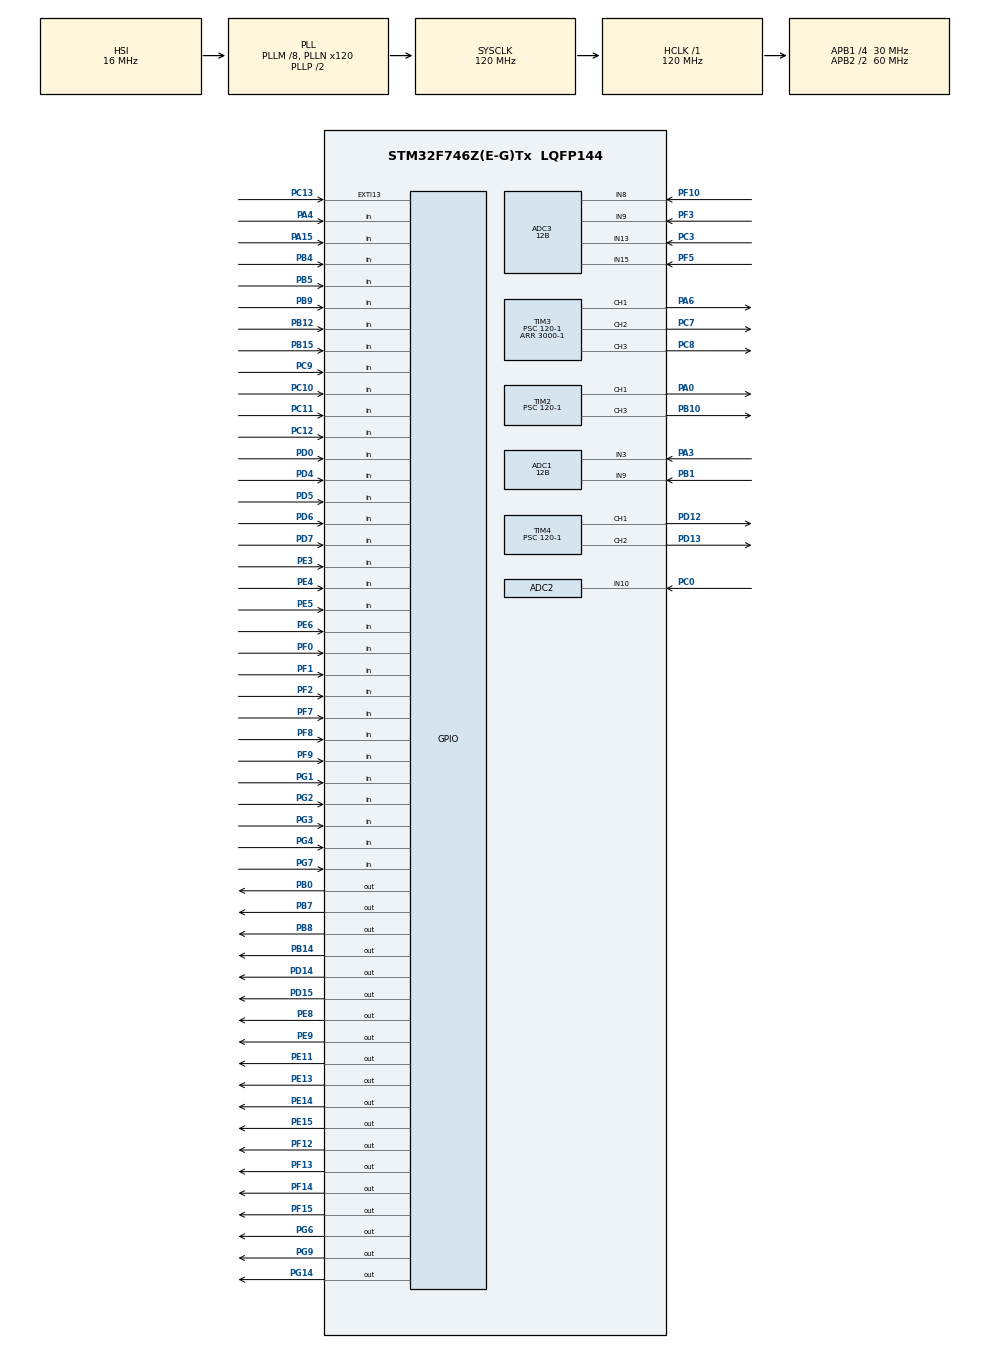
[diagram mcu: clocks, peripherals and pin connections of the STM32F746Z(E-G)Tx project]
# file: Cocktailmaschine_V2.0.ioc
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ADC1.Channel-10\#ChannelRegularConversion=ADC_CHANNEL_TEMPSENSOR
ADC1.Channel-5\#ChannelRegularConversion=ADC_CHANNEL_3
ADC1.Channel-6\#ChannelRegularConversion=ADC_CHANNEL_9
ADC1.ClockPrescaler=ADC_CLOCK_SYNC_PCLK_DIV4
ADC1.ContinuousConvMode=ENABLE
ADC1.DMAContinuousRequests=ENABLE
ADC1.DataAlign=ADC_DATAALIGN_RIGHT
ADC1.DiscontinuousConvMode=DISABLE
ADC1.EOCSelection=ADC_EOC_SINGLE_CONV
ADC1.EnableAnalogWatchDog=false
ADC1.ExternalTrigConv=ADC_SOFTWARE_START
ADC1.ExternalTrigConvEdge=ADC_EXTERNALTRIGCONVEDGE_NONE
ADC1.InjNumberOfConversion=0
ADC1.NbrOfConversion=3
ADC1.NbrOfConversionFlag=1
ADC1.Rank-10\#ChannelRegularConversion=3
ADC1.Rank-5\#ChannelRegularConversion=1
ADC1.Rank-6\#ChannelRegularConversion=2
ADC1.Resolution=ADC_RESOLUTION_12B
ADC1.SamplingTime-10\#ChannelRegularConversion=ADC_SAMPLETIME_28CYCLES
ADC1.SamplingTime-5\#ChannelRegularConversion=ADC_SAMPLETIME_28CYCLES
ADC1.SamplingTime-6\#ChannelRegularConversion=ADC_SAMPLETIME_28CYCLES
ADC1.ScanConvMode=ENABLE
ADC1.master=1
ADC2.Channel-0\#ChannelRegularConversion=ADC_CHANNEL_10
ADC2.ClockPrescaler=ADC_CLOCK_SYNC_PCLK_DIV4
ADC2.ContinuousConvMode=ENABLE
ADC2.DMAContinuousRequests=ENABLE
ADC2.DataAlign=ADC_DATAALIGN_RIGHT
ADC2.DiscontinuousConvMode=DISABLE
ADC2.EOCSelection=ADC_EOC_SINGLE_CONV
ADC2.EnableAnalogWatchDog=false
ADC2.ExternalTrigConv=ADC_SOFTWARE_START
ADC2.ExternalTrigConvEdge=ADC_EXTERNALTRIGCONVEDGE_NONE
ADC2.InjNumberOfConversion=0
ADC2.NbrOfConversion=1
ADC2.NbrOfConversionFlag=1
ADC2.Rank-0\#ChannelRegularConversion=1
ADC2.Resolution=ADC_RESOLUTION_12B
ADC2.SamplingTime-0\#ChannelRegularConversion=ADC_SAMPLETIME_28CYCLES
ADC2.ScanConvMode=ENABLE
ADC3.Channel-0\#ChannelRegularConversion=ADC_CHANNEL_8
ADC3.Channel-1\#ChannelRegularConversion=ADC_CHANNEL_9
ADC3.Channel-2\#ChannelRegularConversion=ADC_CHANNEL_13
ADC3.Channel-3\#ChannelRegularConversion=ADC_CHANNEL_15
ADC3.ClockPrescaler=ADC_CLOCK_SYNC_PCLK_DIV4
ADC3.ContinuousConvMode=ENABLE
ADC3.DMAContinuousRequests=ENABLE
ADC3.DataAlign=ADC_DATAALIGN_RIGHT
ADC3.DiscontinuousConvMode=DISABLE
ADC3.EOCSelection=ADC_EOC_SINGLE_CONV
ADC3.EnableAnalogWatchDog=false
ADC3.ExternalTrigConv=ADC_SOFTWARE_START
ADC3.ExternalTrigConvEdge=ADC_EXTERNALTRIGCONVEDGE_NONE
ADC3.InjNumberOfConversion=0
ADC3.NbrOfConversion=4
ADC3.NbrOfConversionFlag=1
ADC3.Rank-0\#ChannelRegularConversion=1
ADC3.Rank-1\#ChannelRegularConversion=2
ADC3.Rank-2\#ChannelRegularConversion=3
ADC3.Rank-3\#ChannelRegularConversion=4
ADC3.Resolution=ADC_RESOLUTION_12B
ADC3.SamplingTime-0\#ChannelRegularConversion=ADC_SAMPLETIME_28CYCLES
ADC3.SamplingTime-1\#ChannelRegularConversion=ADC_SAMPLETIME_28CYCLES
ADC3.SamplingTime-2\#ChannelRegularConversion=ADC_SAMPLETIME_28CYCLES
ADC3.SamplingTime-3\#ChannelRegularConversion=ADC_SAMPLETIME_28CYCLES
ADC3.ScanConvMode=ENABLE
Dma.ADC1.0.Direction=DMA_PERIPH_TO_MEMORY
Dma.ADC1.0.FIFOMode=DMA_FIFOMODE_DISABLE
Dma.ADC1.0.Instance=DMA2_Stream0
Dma.ADC1.0.MemDataAlignment=DMA_MDATAALIGN_WORD
Dma.ADC1.0.MemInc=DMA_MINC_ENABLE
Dma.ADC1.0.Mode=DMA_CIRCULAR
Dma.ADC1.0.PeriphDataAlignment=DMA_PDATAALIGN_WORD
Dma.ADC1.0.PeriphInc=DMA_PINC_DISABLE
Dma.ADC1.0.Priority=DMA_PRIORITY_LOW
Dma.ADC2.1.Direction=DMA_PERIPH_TO_MEMORY
Dma.ADC2.1.FIFOMode=DMA_FIFOMODE_DISABLE
Dma.ADC2.1.Instance=DMA2_Stream2
Dma.ADC2.1.MemDataAlignment=DMA_MDATAALIGN_WORD
Dma.ADC2.1.MemInc=DMA_MINC_ENABLE
Dma.ADC2.1.Mode=DMA_CIRCULAR
Dma.ADC2.1.PeriphDataAlignment=DMA_PDATAALIGN_WORD
Dma.ADC2.1.PeriphInc=DMA_PINC_DISABLE
Dma.ADC2.1.Priority=DMA_PRIORITY_LOW
Dma.ADC3.2.Direction=DMA_PERIPH_TO_MEMORY
Dma.ADC3.2.FIFOMode=DMA_FIFOMODE_DISABLE
Dma.ADC3.2.Instance=DMA2_Stream1
Dma.ADC3.2.MemDataAlignment=DMA_MDATAALIGN_WORD
Dma.ADC3.2.MemInc=DMA_MINC_ENABLE
Dma.ADC3.2.Mode=DMA_CIRCULAR
Dma.ADC3.2.PeriphDataAlignment=DMA_PDATAALIGN_WORD
Dma.ADC3.2.PeriphInc=DMA_PINC_DISABLE
Dma.ADC3.2.Priority=DMA_PRIORITY_LOW
Dma.Request0=ADC1
Dma.Request1=ADC2
Dma.Request2=ADC3
FREERTOS.INCLUDE_vTaskDelayUntil=1
FREERTOS.MEMORY_ALLOCATION=0
FREERTOS.Tasks01=mainCycle,0,256,mainCycleStart,Default,NULL,Dynamic,NULL,NULL;commTask,-1,128,initCommTask,Default,NULL,Dynamic,NULL,NULL
FREERTOS.Timers01=Timer_TestEnv,TestEnvCallback,osTimerPeriodic,Default,NULL,Dynamic,NULL
FREERTOS.configTOTAL_HEAP_SIZE=15000
FREERTOS.configUSE_COUNTING_SEMAPHORES=1
FREERTOS.configUSE_TIMERS=1
Mcu.Family=STM32F7
Mcu.Name=STM32F746Z(E-G)Tx
Mcu.Package=LQFP144
NVIC.DMA2_Stream0_IRQn=true\:5\:0\:false\:false\:true\:true
NVIC.DMA2_Stream1_IRQn=true\:5\:0\:false\:false\:true\:true
NVIC.DMA2_Stream2_IRQn=true\:5\:0\:false\:false\:true\:true
NVIC.PriorityGroup=NVIC_PRIORITYGROUP_4
NVIC.TIM1_UP_TIM10_IRQn=true\:0\:0\:false\:false\:true\:false
NVIC.TimeBase=TIM1_UP_TIM10_IRQn
NVIC.TimeBaseIP=TIM1
PA0/WKUP.Signal=S_TIM2_CH1_ETR
PA1.GPIO_Mode=GPIO_MODE_AF_PP
PA1.GPIO_PuPd=GPIO_NOPULL
PA1.GPIO_Speed=GPIO_SPEED_FREQ_VERY_HIGH
PA1.Signal=ETH_REF_CLK
PA10.GPIO_Mode=GPIO_MODE_AF_PP
PA10.GPIO_PuPd=GPIO_NOPULL
PA10.GPIO_Speed=GPIO_SPEED_FREQ_VERY_HIGH
PA10.Signal=USB_OTG_FS_ID
PA11.GPIO_Mode=GPIO_MODE_AF_PP
PA11.GPIO_PuPd=GPIO_NOPULL
PA11.GPIO_Speed=GPIO_SPEED_FREQ_VERY_HIGH
PA11.Signal=USB_OTG_FS_DM
PA12.GPIO_Mode=GPIO_MODE_AF_PP
PA12.GPIO_PuPd=GPIO_NOPULL
PA12.GPIO_Speed=GPIO_SPEED_FREQ_VERY_HIGH
PA12.Signal=USB_OTG_FS_DP
PA13.Signal=SYS_JTMS-SWDIO
PA14.Signal=SYS_JTCK-SWCLK
PA15.Signal=GPIO_Input
PA2.GPIO_Mode=GPIO_MODE_AF_PP
PA2.GPIO_PuPd=GPIO_NOPULL
PA2.GPIO_Speed=GPIO_SPEED_FREQ_VERY_HIGH
PA2.Signal=ETH_MDIO
PA3.Signal=SharedAnalog_PA3
PA4.GPIO_PuPd=GPIO_PULLUP
PA4.Signal=GPIO_Input
PA6.Signal=S_TIM3_CH1
PA7.GPIO_Mode=GPIO_MODE_AF_PP
PA7.GPIO_PuPd=GPIO_NOPULL
PA7.GPIO_Speed=GPIO_SPEED_FREQ_VERY_HIGH
PA7.Signal=ETH_CRS_DV
PA8.GPIO_Mode=GPIO_MODE_AF_PP
PA8.GPIO_PuPd=GPIO_NOPULL
PA8.GPIO_Speed=GPIO_SPEED_FREQ_VERY_HIGH
PA8.Signal=USB_OTG_FS_SOF
PA9.GPIO_Mode=GPIO_MODE_INPUT
PA9.GPIO_PuPd=GPIO_NOPULL
PA9.Signal=USB_OTG_FS_VBUS
PB0.GPIO_ModeDefaultOutputPP=GPIO_MODE_OUTPUT_PP
PB0.GPIO_PuPd=GPIO_NOPULL
PB0.GPIO_Speed=GPIO_SPEED_FREQ_LOW
PB0.PinState=GPIO_PIN_RESET
PB0.Signal=GPIO_Output
PB1.Signal=SharedAnalog_PB1
PB10.Signal=S_TIM2_CH3
PB12.GPIO_PuPd=GPIO_PULLUP
PB12.Signal=GPIO_Input
PB13.GPIO_Mode=GPIO_MODE_AF_PP
PB13.GPIO_PuPd=GPIO_NOPULL
PB13.GPIO_Speed=GPIO_SPEED_FREQ_VERY_HIGH
PB13.Signal=ETH_TXD1
PB14.GPIO_ModeDefaultOutputPP=GPIO_MODE_OUTPUT_PP
PB14.GPIO_PuPd=GPIO_NOPULL
PB14.GPIO_Speed=GPIO_SPEED_FREQ_LOW
PB14.PinState=GPIO_PIN_RESET
PB14.Signal=GPIO_Output
PB15.Signal=GPIO_Input
PB3.Signal=SYS_JTDO-SWO
PB4.GPIO_PuPd=GPIO_PULLUP
PB4.Signal=GPIO_Input
PB5.GPIO_PuPd=GPIO_PULLUP
PB5.Signal=GPIO_Input
PB7.GPIO_ModeDefaultOutputPP=GPIO_MODE_OUTPUT_PP
PB7.GPIO_PuPd=GPIO_NOPULL
PB7.GPIO_Speed=GPIO_SPEED_FREQ_LOW
PB7.PinState=GPIO_PIN_RESET
PB7.Signal=GPIO_Output
PB8.Signal=GPIO_Output
PB9.Signal=GPIO_Input
PC0.Signal=SharedAnalog_PC0
PC1.GPIO_Mode=GPIO_MODE_AF_PP
PC1.GPIO_PuPd=GPIO_NOPULL
PC1.GPIO_Speed=GPIO_SPEED_FREQ_VERY_HIGH
PC1.Signal=ETH_MDC
PC10.GPIO_Mode=GPIO_MODE_INPUT
PC10.GPIO_PuPd=GPIO_PULLUP
PC10.Signal=GPIO_Input
PC11.GPIO_Mode=GPIO_MODE_INPUT
PC11.GPIO_PuPd=GPIO_PULLUP
PC11.Signal=GPIO_Input
PC12.GPIO_Mode=GPIO_MODE_INPUT
PC12.GPIO_PuPd=GPIO_PULLUP
PC12.Signal=GPIO_Input
PC13.GPIO_ModeDefaultEXTI=GPIO_MODE_IT_RISING
PC13.GPIO_PuPd=GPIO_NOPULL
PC13.Signal=GPXTI13
PC14/OSC32_IN.Signal=RCC_OSC32_IN
PC15/OSC32_OUT.Signal=RCC_OSC32_OUT
PC3.Signal=SharedAnalog_PC3
PC4.GPIO_Mode=GPIO_MODE_AF_PP
PC4.GPIO_PuPd=GPIO_NOPULL
PC4.GPIO_Speed=GPIO_SPEED_FREQ_VERY_HIGH
PC4.Signal=ETH_RXD0
PC5.GPIO_Mode=GPIO_MODE_AF_PP
PC5.GPIO_PuPd=GPIO_NOPULL
PC5.GPIO_Speed=GPIO_SPEED_FREQ_VERY_HIGH
PC5.Signal=ETH_RXD1
PC7.Signal=S_TIM3_CH2
PC8.Signal=S_TIM3_CH3
PC9.GPIO_Mode=GPIO_MODE_INPUT
PC9.GPIO_PuPd=GPIO_PULLUP
PC9.Signal=GPIO_Input
PD0.Signal=GPIO_Input
PD12.Signal=S_TIM4_CH1
PD13.Signal=S_TIM4_CH2
PD14.Signal=GPIO_Output
PD15.Signal=GPIO_Output
PD4.GPIO_Mode=GPIO_MODE_INPUT
PD4.GPIO_PuPd=GPIO_PULLUP
PD4.Signal=GPIO_Input
PD5.GPIO_Mode=GPIO_MODE_INPUT
PD5.GPIO_PuPd=GPIO_PULLUP
PD5.Signal=GPIO_Input
PD6.GPIO_Mode=GPIO_MODE_INPUT
PD6.GPIO_PuPd=GPIO_PULLUP
PD6.Signal=GPIO_Input
PD7.GPIO_Mode=GPIO_MODE_INPUT
PD7.GPIO_PuPd=GPIO_PULLUP
PD7.Signal=GPIO_Input
PD8.GPIO_Mode=GPIO_MODE_AF_PP
PD8.GPIO_PuPd=GPIO_NOPULL
PD8.GPIO_Speed=GPIO_SPEED_FREQ_VERY_HIGH
PD8.Signal=USART3_TX
PD9.GPIO_Mode=GPIO_MODE_AF_PP
PD9.GPIO_PuPd=GPIO_NOPULL
PD9.GPIO_Speed=GPIO_SPEED_FREQ_VERY_HIGH
PD9.Signal=USART3_RX
PE11.Signal=GPIO_Output
PE13.Signal=GPIO_Output
PE14.Signal=GPIO_Output
PE15.Signal=GPIO_Output
PE3.Signal=GPIO_Input
PE4.Signal=GPIO_Input
PE5.Signal=GPIO_Input
PE6.Signal=GPIO_Input
PE7.Signal=UART7_RX
PE8.Signal=GPIO_Output
PE9.Signal=GPIO_Output
PF0.Signal=GPIO_Input
PF1.Signal=GPIO_Input
PF10.Signal=SharedAnalog_PF10
PF12.Signal=GPIO_Output
PF13.Signal=GPIO_Output
PF14.Signal=GPIO_Output
PF15.Signal=GPIO_Output
PF2.Signal=GPIO_Input
PF3.Signal=SharedAnalog_PF3
PF5.Signal=SharedAnalog_PF5
PF7.GPIO_PuPd=GPIO_NOPULL
PF7.Signal=GPIO_Input
PF8.GPIO_PuPd=GPIO_NOPULL
PF8.Signal=GPIO_Input
PF9.Signal=GPIO_Input
PG1.GPIO_PuPd=GPIO_NOPULL
PG1.Signal=GPIO_Input
PG11.GPIO_Mode=GPIO_MODE_AF_PP
PG11.GPIO_PuPd=GPIO_NOPULL
PG11.GPIO_Speed=GPIO_SPEED_FREQ_VERY_HIGH
PG11.Signal=ETH_TX_EN
PG13.GPIO_Mode=GPIO_MODE_AF_PP
PG13.GPIO_PuPd=GPIO_NOPULL
PG13.GPIO_Speed=GPIO_SPEED_FREQ_VERY_HIGH
PG13.Signal=ETH_TXD0
PG14.Signal=GPIO_Output
PG2.GPIO_PuPd=GPIO_PULLUP
PG2.Signal=GPIO_Input
PG3.GPIO_PuPd=GPIO_PULLUP
PG3.Signal=GPIO_Input
PG4.GPIO_PuPd=GPIO_PULLUP
PG4.Signal=GPIO_Input
PG6.GPIO_ModeDefaultOutputPP=GPIO_MODE_OUTPUT_PP
PG6.GPIO_PuPd=GPIO_NOPULL
PG6.GPIO_Speed=GPIO_SPEED_FREQ_LOW
PG6.PinState=GPIO_PIN_RESET
PG6.Signal=GPIO_Output
PG7.GPIO_Mode=GPIO_MODE_INPUT
PG7.GPIO_PuPd=GPIO_NOPULL
PG7.Signal=GPIO_Input
PG9.Signal=GPIO_Output
PH0/OSC_IN.Signal=RCC_OSC_IN
PH1/OSC_OUT.Signal=RCC_OSC_OUT
ProjectManager.HeapSize=0x200
ProjectManager.StackSize=0x400
ProjectManager.TargetToolchain=TrueSTUDIO
RCC.48MHZClocksFreq_Value=24000000
RCC.AHBFreq_Value=120000000
RCC.APB1CLKDivider=RCC_HCLK_DIV4
RCC.APB1Freq_Value=30000000
RCC.APB1TimFreq_Value=60000000
RCC.APB2CLKDivider=RCC_HCLK_DIV2
RCC.APB2Freq_Value=60000000
RCC.APB2TimFreq_Value=120000000
RCC.CortexFreq_Value=120000000
RCC.HCLKFreq_Value=120000000
RCC.HSE_VALUE=8000000
RCC.HSI_VALUE=16000000
RCC.LSE_VALUE=32768
RCC.PLLM=8
RCC.PLLMUL=RCC_PLL_MUL9
RCC.PLLN=120
RCC.PLLQ=5
RCC.PRESCALERUSB=RCC_USBCLKSOURCE_PLL_DIV1_5
RCC.SYSCLKFreq_VALUE=120000000
RCC.SYSCLKSource=RCC_SYSCLKSOURCE_PLLCLK
RCC.SYSCLKSourceVirtual=RCC_SYSCLKSOURCE_PLLCLK
RCC.USBFreq_Value=48000000
RCC.VCOOutputFreq_Value=240000000
SH.S_TIM2_CH1_ETR.0=TIM2_CH1,PWM Generation1 CH1
SH.S_TIM2_CH3.0=TIM2_CH3,PWM Generation3 CH3
SH.S_TIM3_CH1.0=TIM3_CH1,PWM Generation1 CH1
SH.S_TIM3_CH2.0=TIM3_CH2,PWM Generation2 CH2
SH.S_TIM3_CH3.0=TIM3_CH3,PWM Generation3 CH3
SH.S_TIM4_CH1.0=TIM4_CH1,PWM Generation1 CH1
SH.S_TIM4_CH2.0=TIM4_CH2,PWM Generation2 CH2
SH.SharedAnalog_PA3.0=GPIO_Analog
SH.SharedAnalog_PA3.1=ADC1_IN3,IN3
SH.SharedAnalog_PB1.0=GPIO_Analog
SH.SharedAnalog_PB1.1=ADC1_IN9,IN9
SH.SharedAnalog_PC0.0=GPIO_Analog
SH.SharedAnalog_PC0.1=ADC2_IN10,IN10
SH.SharedAnalog_PC3.0=GPIO_Analog
SH.SharedAnalog_PC3.1=ADC3_IN13,IN13
SH.SharedAnalog_PF10.0=GPIO_Analog
SH.SharedAnalog_PF10.1=ADC3_IN8,IN8
SH.SharedAnalog_PF3.0=GPIO_Analog
SH.SharedAnalog_PF3.1=ADC3_IN9,IN9
SH.SharedAnalog_PF5.0=GPIO_Analog
SH.SharedAnalog_PF5.1=ADC3_IN15,IN15
TIM2.Channel-PWM\ Generation1\ CH1=TIM_CHANNEL_1
TIM2.Channel-PWM\ Generation3\ CH3=TIM_CHANNEL_3
TIM2.Period=3000-1
TIM2.Prescaler=120-1
TIM3.Channel-PWM\ Generation1\ CH1=TIM_CHANNEL_1
TIM3.Channel-PWM\ Generation2\ CH2=TIM_CHANNEL_2
TIM3.Channel-PWM\ Generation3\ CH3=TIM_CHANNEL_3
TIM3.Period=3000-1
TIM3.Prescaler=120-1
TIM4.Channel-PWM\ Generation1\ CH1=TIM_CHANNEL_1
TIM4.Channel-PWM\ Generation2\ CH2=TIM_CHANNEL_2
TIM4.Period=3000-1
TIM4.Prescaler=120-1
VP_ADC1_TempSens_Input.Mode=IN-TempSens
VP_FREERTOS_VS_ENABLE.Mode=Enabled
VP_SYS_VS_tim1.Mode=TIM1
board=NUCLEO-F746ZG

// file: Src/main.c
/**
  ******************************************************************************
  * File Name          : main.c
  * Description        : Main program body
  ******************************************************************************
  * This notice applies to any and all portions of this file
  * that are not between comment pairs USER CODE BEGIN and
  * USER CODE END. Other portions of this file, whether
  * inserted by the user or by software development tools
  * are owned by their respective copyright owners.
  *
  * Copyright (c) 2017 STMicroelectronics International N.V.
  * All rights reserved.
  *
  * Redistribution and use in source and binary forms, with or without
  * modification, are permitted, provided that the following conditions are met:
  *
  * 1. Redistribution of source code must retain the above copyright notice,
  *    this list of conditions and the following disclaimer.
  * 2. Redistributions in binary form must reproduce the above copyright notice,
  *    this list of conditions and the following disclaimer in the documentation
  *    and/or other materials provided with the distribution.
  * 3. Neither the name of STMicroelectronics nor the names of other
  *    contributors to this software may be used to endorse or promote products
  *    derived from this software without specific written permission.
  * 4. This software, including modifications and/or derivative works of this
  *    software, must execute solely and exclusively on microcontroller or
  *    microprocessor devices manufactured by or for STMicroelectronics.
  * 5. Redistribution and use of this software other than as permitted under
  *    this license is void and will automatically terminate your rights under
  *    this license.
  *
  * THIS SOFTWARE IS PROVIDED BY STMICROELECTRONICS AND CONTRIBUTORS "AS IS"
  * AND ANY EXPRESS, IMPLIED OR STATUTORY WARRANTIES, INCLUDING, BUT NOT
  * LIMITED TO, THE IMPLIED WARRANTIES OF MERCHANTABILITY, FITNESS FOR A
  * PARTICULAR PURPOSE AND NON-INFRINGEMENT OF THIRD PARTY INTELLECTUAL PROPERTY
  * RIGHTS ARE DISCLAIMED TO THE FULLEST EXTENT PERMITTED BY LAW. IN NO EVENT
  * SHALL STMICROELECTRONICS OR CONTRIBUTORS BE LIABLE FOR ANY DIRECT, INDIRECT,
  * INCIDENTAL, SPECIAL, EXEMPLARY, OR CONSEQUENTIAL DAMAGES (INCLUDING, BUT NOT
  * LIMITED TO, PROCUREMENT OF SUBSTITUTE GOODS OR SERVICES; LOSS OF USE, DATA,
  * OR PROFITS; OR BUSINESS INTERRUPTION) HOWEVER CAUSED AND ON ANY THEORY OF
  * LIABILITY, WHETHER IN CONTRACT, STRICT LIABILITY, OR TORT (INCLUDING
  * NEGLIGENCE OR OTHERWISE) ARISING IN ANY WAY OUT OF THE USE OF THIS SOFTWARE,
  * EVEN IF ADVISED OF THE POSSIBILITY OF SUCH DAMAGE.
  *
  ******************************************************************************
  */
#include "main.h"
#include "stm32f7xx_hal.h"
#include "cmsis_os.h"

/* USER CODE BEGIN Includes */
#include "Sensors.h"
#include "Evaluation.h"
#include "Module_5_Sensors.h"
#include "Module_common.h"
#include "Actuators.h"
#include "Communication.h"

#define DEBUG_ENABLED 1
#include "Debug.h"

#include "FreeRTOS.h"
#include "task.h"
#include "stm32f7xx_nucleo_144.h"

/* USER CODE END Includes */

ADC_HandleTypeDef hadc1;
ADC_HandleTypeDef hadc2;
ADC_HandleTypeDef hadc3;
DMA_HandleTypeDef hdma_adc1;
DMA_HandleTypeDef hdma_adc2;
DMA_HandleTypeDef hdma_adc3;

TIM_HandleTypeDef htim2;
TIM_HandleTypeDef htim3;
TIM_HandleTypeDef htim4;

osThreadId mainCycleHandle;
osThreadId commTaskHandle;
osTimerId Timer_TestEnvHandle;

/* USER CODE BEGIN PV */
/* Private variables ---------------------------------------------------------*/
InputValues_t Input_Storage;
OutputValues_t Output_Storage;
SystemState_t System_State;

osThreadId mainCycleHandle;

extern int virtual_testenv_timer_variable;

/* USER CODE END PV */

void SystemClock_Config(void);
static void MX_GPIO_Init(void);
static void MX_DMA_Init(void);
static void MX_ADC1_Init(void);
static void MX_ADC2_Init(void);
static void MX_ADC3_Init(void);
static void MX_TIM3_Init(void);
static void MX_TIM4_Init(void);
static void MX_TIM2_Init(void);
void mainCycleStart(void const * argument);
void initCommTask(void const * argument);
void TestEnvCallback(void const * argument);

void HAL_TIM_MspPostInit(TIM_HandleTypeDef *htim);

/* USER CODE BEGIN PFP */
/* Private function prototypes -----------------------------------------------*/

/* USER CODE END PFP */

int main(void)
{

  /* MCU Configuration----------------------------------------------------------*/

  /* Reset of all peripherals, Initializes the Flash interface and the Systick. */
  HAL_Init();

  /* Configure the system clock */
  SystemClock_Config();

  /* Initialize all configured peripherals */
  MX_GPIO_Init();
  MX_DMA_Init();
  MX_ADC1_Init();
  MX_ADC2_Init();
  MX_ADC3_Init();
  MX_TIM3_Init();
  MX_TIM4_Init();
  MX_TIM2_Init();

  /* USER CODE BEGIN 2 */
  if(HAL_ADC_Start(&hadc1) != HAL_OK)
  {
	  printf("ADC not ok! \r\n");
	  return 0;
  }
  if(HAL_ADC_Start_DMA(&hadc1, (uint32_t*)ADC1ConvertedValues,12)!= HAL_OK)
  {
	  printf("DMA not ok! \r\n");
	  return 0;
  }
  if(HAL_ADC_Start(&hadc2) != HAL_OK)
  {
	  printf("ADC not ok! \r\n");
	  return 0;
  }
  if(HAL_ADC_Start_DMA(&hadc2, (uint32_t*)ADC2ConvertedValues,1)!= HAL_OK)
  {
	  printf("DMA not ok! \r\n");
	  return 0;
  }
  if(HAL_ADC_Start(&hadc3) != HAL_OK)
  {
	  printf("ADC not ok! \r\n");
	  return 0;
  }
  if(HAL_ADC_Start_DMA(&hadc3, (uint32_t*)ADC3ConvertedValues,4)!= HAL_OK)
  {
	  printf("DMA not ok! \r\n");
	  return 0;
  }

  /*FreeRTOS_IPInit( ucIPAddress,
                   ucNetMask,
                   ucGatewayAddress,
                   ucDNSServerAddress,
                   ucMACAddress );*/
  /* USER CODE END 2 */

  /* Create the timer(s) */
  /* definition and creation of Timer_TestEnv */
  osTimerDef(Timer_TestEnv, TestEnvCallback);
  Timer_TestEnvHandle = osTimerCreate(osTimer(Timer_TestEnv), osTimerPeriodic, NULL);

  /* Create the thread(s) */
  /* definition and creation of mainCycle */
  osThreadDef(mainCycle, mainCycleStart, osPriorityNormal, 0, 256);
  mainCycleHandle = osThreadCreate(osThread(mainCycle), NULL);

  /* definition and creation of commTask */
  osThreadDef(commTask, initCommTask, osPriorityBelowNormal, 0, 128);
  commTaskHandle = osThreadCreate(osThread(commTask), NULL);

  /* Start scheduler */
  osKernelStart();

  /* We should never get here as control is now taken by the scheduler */

  /* Infinite loop */
  while (1)
  {

  }

}

/** System Clock Configuration
*/
void SystemClock_Config(void)
{

  RCC_OscInitTypeDef RCC_OscInitStruct;
  RCC_ClkInitTypeDef RCC_ClkInitStruct;

    /**Configure the main internal regulator output voltage
    */
  __HAL_RCC_PWR_CLK_ENABLE();

  __HAL_PWR_VOLTAGESCALING_CONFIG(PWR_REGULATOR_VOLTAGE_SCALE3);

    /**Initializes the CPU, AHB and APB busses clocks
    */
  RCC_OscInitStruct.OscillatorType = RCC_OSCILLATORTYPE_HSI;
  RCC_OscInitStruct.HSIState = RCC_HSI_ON;
  RCC_OscInitStruct.HSICalibrationValue = 16;
  RCC_OscInitStruct.PLL.PLLState = RCC_PLL_ON;
  RCC_OscInitStruct.PLL.PLLSource = RCC_PLLSOURCE_HSI;
  RCC_OscInitStruct.PLL.PLLM = 8;
  RCC_OscInitStruct.PLL.PLLN = 120;
  RCC_OscInitStruct.PLL.PLLP = RCC_PLLP_DIV2;
  RCC_OscInitStruct.PLL.PLLQ = 5;
  if (HAL_RCC_OscConfig(&RCC_OscInitStruct) != HAL_OK)
  {
    _Error_Handler(__FILE__, __LINE__);
  }

    /**Initializes the CPU, AHB and APB busses clocks
    */
  RCC_ClkInitStruct.ClockType = RCC_CLOCKTYPE_HCLK|RCC_CLOCKTYPE_SYSCLK
                              |RCC_CLOCKTYPE_PCLK1|RCC_CLOCKTYPE_PCLK2;
  RCC_ClkInitStruct.SYSCLKSource = RCC_SYSCLKSOURCE_PLLCLK;
  RCC_ClkInitStruct.AHBCLKDivider = RCC_SYSCLK_DIV1;
  RCC_ClkInitStruct.APB1CLKDivider = RCC_HCLK_DIV4;
  RCC_ClkInitStruct.APB2CLKDivider = RCC_HCLK_DIV2;

  if (HAL_RCC_ClockConfig(&RCC_ClkInitStruct, FLASH_LATENCY_3) != HAL_OK)
  {
    _Error_Handler(__FILE__, __LINE__);
  }

    /**Configure the Systick interrupt time
    */
  HAL_SYSTICK_Config(HAL_RCC_GetHCLKFreq()/1000);

    /**Configure the Systick
    */
  HAL_SYSTICK_CLKSourceConfig(SYSTICK_CLKSOURCE_HCLK);

  /* SysTick_IRQn interrupt configuration */
  HAL_NVIC_SetPriority(SysTick_IRQn, 15, 0);
}

/* ADC1 init function */
static void MX_ADC1_Init(void)
{

  ADC_ChannelConfTypeDef sConfig;

    /**Configure the global features of the ADC (Clock, Resolution, Data Alignment and number of conversion)
    */
  hadc1.Instance = ADC1;
  hadc1.Init.ClockPrescaler = ADC_CLOCK_SYNC_PCLK_DIV4;
  hadc1.Init.Resolution = ADC_RESOLUTION_12B;
  hadc1.Init.ScanConvMode = ENABLE;
  hadc1.Init.ContinuousConvMode = ENABLE;
  hadc1.Init.DiscontinuousConvMode = DISABLE;
  hadc1.Init.ExternalTrigConvEdge = ADC_EXTERNALTRIGCONVEDGE_NONE;
  hadc1.Init.ExternalTrigConv = ADC_SOFTWARE_START;
  hadc1.Init.DataAlign = ADC_DATAALIGN_RIGHT;
  hadc1.Init.NbrOfConversion = 3;
  hadc1.Init.DMAContinuousRequests = ENABLE;
  hadc1.Init.EOCSelection = ADC_EOC_SINGLE_CONV;
  if (HAL_ADC_Init(&hadc1) != HAL_OK)
  {
    _Error_Handler(__FILE__, __LINE__);
  }

    /**Configure for the selected ADC regular channel its corresponding rank in the sequencer and its sample time.
    */
  sConfig.Channel = ADC_CHANNEL_3;
  sConfig.Rank = 1;
  sConfig.SamplingTime = ADC_SAMPLETIME_28CYCLES;
  if (HAL_ADC_ConfigChannel(&hadc1, &sConfig) != HAL_OK)
  {
    _Error_Handler(__FILE__, __LINE__);
  }

    /**Configure for the selected ADC regular channel its corresponding rank in the sequencer and its sample time.
    */
  sConfig.Channel = ADC_CHANNEL_9;
  sConfig.Rank = 2;
  if (HAL_ADC_ConfigChannel(&hadc1, &sConfig) != HAL_OK)
  {
    _Error_Handler(__FILE__, __LINE__);
  }

    /**Configure for the selected ADC regular channel its corresponding rank in the sequencer and its sample time.
    */
  sConfig.Channel = ADC_CHANNEL_TEMPSENSOR;
  sConfig.Rank = 3;
  if (HAL_ADC_ConfigChannel(&hadc1, &sConfig) != HAL_OK)
  {
    _Error_Handler(__FILE__, __LINE__);
  }

}

/* ADC2 init function */
static void MX_ADC2_Init(void)
{

  ADC_ChannelConfTypeDef sConfig;

    /**Configure the global features of the ADC (Clock, Resolution, Data Alignment and number of conversion)
    */
  hadc2.Instance = ADC2;
  hadc2.Init.ClockPrescaler = ADC_CLOCK_SYNC_PCLK_DIV4;
  hadc2.Init.Resolution = ADC_RESOLUTION_12B;
  hadc2.Init.ScanConvMode = ENABLE;
  hadc2.Init.ContinuousConvMode = ENABLE;
  hadc2.Init.DiscontinuousConvMode = DISABLE;
  hadc2.Init.ExternalTrigConvEdge = ADC_EXTERNALTRIGCONVEDGE_NONE;
  hadc2.Init.ExternalTrigConv = ADC_SOFTWARE_START;
  hadc2.Init.DataAlign = ADC_DATAALIGN_RIGHT;
  hadc2.Init.NbrOfConversion = 1;
  hadc2.Init.DMAContinuousRequests = ENABLE;
  hadc2.Init.EOCSelection = ADC_EOC_SINGLE_CONV;
  if (HAL_ADC_Init(&hadc2) != HAL_OK)
  {
    _Error_Handler(__FILE__, __LINE__);
  }

    /**Configure for the selected ADC regular channel its corresponding rank in the sequencer and its sample time.
    */
  sConfig.Channel = ADC_CHANNEL_10;
  sConfig.Rank = 1;
  sConfig.SamplingTime = ADC_SAMPLETIME_28CYCLES;
  if (HAL_ADC_ConfigChannel(&hadc2, &sConfig) != HAL_OK)
  {
    _Error_Handler(__FILE__, __LINE__);
  }

}

/* ADC3 init function */
static void MX_ADC3_Init(void)
{

  ADC_ChannelConfTypeDef sConfig;

    /**Configure the global features of the ADC (Clock, Resolution, Data Alignment and number of conversion)
    */
  hadc3.Instance = ADC3;
  hadc3.Init.ClockPrescaler = ADC_CLOCK_SYNC_PCLK_DIV4;
  hadc3.Init.Resolution = ADC_RESOLUTION_12B;
  hadc3.Init.ScanConvMode = ENABLE;
  hadc3.Init.ContinuousConvMode = ENABLE;
  hadc3.Init.DiscontinuousConvMode = DISABLE;
  hadc3.Init.ExternalTrigConvEdge = ADC_EXTERNALTRIGCONVEDGE_NONE;
  hadc3.Init.ExternalTrigConv = ADC_SOFTWARE_START;
  hadc3.Init.DataAlign = ADC_DATAALIGN_RIGHT;
  hadc3.Init.NbrOfConversion = 4;
  hadc3.Init.DMAContinuousRequests = ENABLE;
  hadc3.Init.EOCSelection = ADC_EOC_SINGLE_CONV;
  if (HAL_ADC_Init(&hadc3) != HAL_OK)
  {
    _Error_Handler(__FILE__, __LINE__);
  }

    /**Configure for the selected ADC regular channel its corresponding rank in the sequencer and its sample time.
    */
  sConfig.Channel = ADC_CHANNEL_8;
  sConfig.Rank = 1;
  sConfig.SamplingTime = ADC_SAMPLETIME_28CYCLES;
  if (HAL_ADC_ConfigChannel(&hadc3, &sConfig) != HAL_OK)
  {
    _Error_Handler(__FILE__, __LINE__);
  }

    /**Configure for the selected ADC regular channel its corresponding rank in the sequencer and its sample time.
    */
  sConfig.Channel = ADC_CHANNEL_9;
  sConfig.Rank = 2;
  if (HAL_ADC_ConfigChannel(&hadc3, &sConfig) != HAL_OK)
  {
    _Error_Handler(__FILE__, __LINE__);
  }

    /**Configure for the selected ADC regular channel its corresponding rank in the sequencer and its sample time.
    */
  sConfig.Channel = ADC_CHANNEL_13;
  sConfig.Rank = 3;
  if (HAL_ADC_ConfigChannel(&hadc3, &sConfig) != HAL_OK)
  {
    _Error_Handler(__FILE__, __LINE__);
  }

    /**Configure for the selected ADC regular channel its corresponding rank in the sequencer and its sample time.
    */
  sConfig.Channel = ADC_CHANNEL_15;
  sConfig.Rank = 4;
  if (HAL_ADC_ConfigChannel(&hadc3, &sConfig) != HAL_OK)
  {
    _Error_Handler(__FILE__, __LINE__);
  }

}

/* TIM2 init function */
static void MX_TIM2_Init(void)
{

  TIM_MasterConfigTypeDef sMasterConfig;
  TIM_OC_InitTypeDef sConfigOC;

  htim2.Instance = TIM2;
  htim2.Init.Prescaler = 120-1;
  htim2.Init.CounterMode = TIM_COUNTERMODE_UP;
  htim2.Init.Period = 3000-1;
  htim2.Init.ClockDivision = TIM_CLOCKDIVISION_DIV1;
  htim2.Init.AutoReloadPreload = TIM_AUTORELOAD_PRELOAD_DISABLE;
  if (HAL_TIM_PWM_Init(&htim2) != HAL_OK)
  {
    _Error_Handler(__FILE__, __LINE__);
  }

  sMasterConfig.MasterOutputTrigger = TIM_TRGO_RESET;
  sMasterConfig.MasterSlaveMode = TIM_MASTERSLAVEMODE_DISABLE;
  if (HAL_TIMEx_MasterConfigSynchronization(&htim2, &sMasterConfig) != HAL_OK)
  {
    _Error_Handler(__FILE__, __LINE__);
  }

  sConfigOC.OCMode = TIM_OCMODE_PWM1;
  sConfigOC.Pulse = 0;
  sConfigOC.OCPolarity = TIM_OCPOLARITY_HIGH;
  sConfigOC.OCFastMode = TIM_OCFAST_DISABLE;
  if (HAL_TIM_PWM_ConfigChannel(&htim2, &sConfigOC, TIM_CHANNEL_1) != HAL_OK)
  {
    _Error_Handler(__FILE__, __LINE__);
  }

  if (HAL_TIM_PWM_ConfigChannel(&htim2, &sConfigOC, TIM_CHANNEL_3) != HAL_OK)
  {
    _Error_Handler(__FILE__, __LINE__);
  }

  HAL_TIM_MspPostInit(&htim2);

}

/* TIM3 init function */
static void MX_TIM3_Init(void)
{

  TIM_MasterConfigTypeDef sMasterConfig;
  TIM_OC_InitTypeDef sConfigOC;

  htim3.Instance = TIM3;
  htim3.Init.Prescaler = 120-1;
  htim3.Init.CounterMode = TIM_COUNTERMODE_UP;
  htim3.Init.Period = 3000-1;
  htim3.Init.ClockDivision = TIM_CLOCKDIVISION_DIV1;
  htim3.Init.AutoReloadPreload = TIM_AUTORELOAD_PRELOAD_DISABLE;
  if (HAL_TIM_PWM_Init(&htim3) != HAL_OK)
  {
    _Error_Handler(__FILE__, __LINE__);
  }

  sMasterConfig.MasterOutputTrigger = TIM_TRGO_RESET;
  sMasterConfig.MasterSlaveMode = TIM_MASTERSLAVEMODE_DISABLE;
  if (HAL_TIMEx_MasterConfigSynchronization(&htim3, &sMasterConfig) != HAL_OK)
  {
    _Error_Handler(__FILE__, __LINE__);
  }

  sConfigOC.OCMode = TIM_OCMODE_PWM1;
  sConfigOC.Pulse = 0;
  sConfigOC.OCPolarity = TIM_OCPOLARITY_HIGH;
  sConfigOC.OCFastMode = TIM_OCFAST_DISABLE;
  if (HAL_TIM_PWM_ConfigChannel(&htim3, &sConfigOC, TIM_CHANNEL_1) != HAL_OK)
  {
    _Error_Handler(__FILE__, __LINE__);
  }

  if (HAL_TIM_PWM_ConfigChannel(&htim3, &sConfigOC, TIM_CHANNEL_2) != HAL_OK)
  {
    _Error_Handler(__FILE__, __LINE__);
  }

  if (HAL_TIM_PWM_ConfigChannel(&htim3, &sConfigOC, TIM_CHANNEL_3) != HAL_OK)
  {
    _Error_Handler(__FILE__, __LINE__);
  }

  HAL_TIM_MspPostInit(&htim3);

}

/* TIM4 init function */
static void MX_TIM4_Init(void)
{

  TIM_MasterConfigTypeDef sMasterConfig;
  TIM_OC_InitTypeDef sConfigOC;

  htim4.Instance = TIM4;
  htim4.Init.Prescaler = 120-1;
  htim4.Init.CounterMode = TIM_COUNTERMODE_UP;
  htim4.Init.Period = 3000-1;
  htim4.Init.ClockDivision = TIM_CLOCKDIVISION_DIV1;
  htim4.Init.AutoReloadPreload = TIM_AUTORELOAD_PRELOAD_DISABLE;
  if (HAL_TIM_PWM_Init(&htim4) != HAL_OK)
  {
    _Error_Handler(__FILE__, __LINE__);
  }

  sMasterConfig.MasterOutputTrigger = TIM_TRGO_RESET;
  sMasterConfig.MasterSlaveMode = TIM_MASTERSLAVEMODE_DISABLE;
  if (HAL_TIMEx_MasterConfigSynchronization(&htim4, &sMasterConfig) != HAL_OK)
  {
    _Error_Handler(__FILE__, __LINE__);
  }

  sConfigOC.OCMode = TIM_OCMODE_PWM1;
  sConfigOC.Pulse = 0;
  sConfigOC.OCPolarity = TIM_OCPOLARITY_HIGH;
  sConfigOC.OCFastMode = TIM_OCFAST_DISABLE;
  if (HAL_TIM_PWM_ConfigChannel(&htim4, &sConfigOC, TIM_CHANNEL_1) != HAL_OK)
  {
    _Error_Handler(__FILE__, __LINE__);
  }

  if (HAL_TIM_PWM_ConfigChannel(&htim4, &sConfigOC, TIM_CHANNEL_2) != HAL_OK)
  {
    _Error_Handler(__FILE__, __LINE__);
  }

  HAL_TIM_MspPostInit(&htim4);

}

static void MX_DMA_Init(void)
{
  /* DMA controller clock enable */
  __HAL_RCC_DMA2_CLK_ENABLE();

  /* DMA interrupt init */
  /* DMA2_Stream0_IRQn interrupt configuration */
  HAL_NVIC_SetPriority(DMA2_Stream0_IRQn, 5, 0);
  HAL_NVIC_EnableIRQ(DMA2_Stream0_IRQn);
  /* DMA2_Stream1_IRQn interrupt configuration */
  HAL_NVIC_SetPriority(DMA2_Stream1_IRQn, 5, 0);
  HAL_NVIC_EnableIRQ(DMA2_Stream1_IRQn);
  /* DMA2_Stream2_IRQn interrupt configuration */
  HAL_NVIC_SetPriority(DMA2_Stream2_IRQn, 5, 0);
  HAL_NVIC_EnableIRQ(DMA2_Stream2_IRQn);

}

/** Configure pins as
        * Analog
        * Input
        * Output
        * EVENT_OUT
        * EXTI
     PF3   ------> SharedAnalog_PF3
     PF5   ------> SharedAnalog_PF5
     PF10   ------> SharedAnalog_PF10
     PC0   ------> SharedAnalog_PC0
     PC1   ------> ETH_MDC
     PC3   ------> SharedAnalog_PC3
     PA1   ------> ETH_REF_CLK
     PA2   ------> ETH_MDIO
     PA3   ------> SharedAnalog_PA3
     PA7   ------> ETH_CRS_DV
     PC4   ------> ETH_RXD0
     PC5   ------> ETH_RXD1
     PB1   ------> SharedAnalog_PB1
     PE7   ------> UART7_RX
     PB13   ------> ETH_TXD1
     PD8   ------> USART3_TX
     PD9   ------> USART3_RX
     PA8   ------> USB_OTG_FS_SOF
     PA9   ------> USB_OTG_FS_VBUS
     PA10   ------> USB_OTG_FS_ID
     PA11   ------> USB_OTG_FS_DM
     PA12   ------> USB_OTG_FS_DP
     PG11   ------> ETH_TX_EN
     PG13   ------> ETH_TXD0
*/
static void MX_GPIO_Init(void)
{

  GPIO_InitTypeDef GPIO_InitStruct;

  /* GPIO Ports Clock Enable */
  __HAL_RCC_GPIOE_CLK_ENABLE();
  __HAL_RCC_GPIOC_CLK_ENABLE();
  __HAL_RCC_GPIOF_CLK_ENABLE();
  __HAL_RCC_GPIOH_CLK_ENABLE();
  __HAL_RCC_GPIOA_CLK_ENABLE();
  __HAL_RCC_GPIOB_CLK_ENABLE();
  __HAL_RCC_GPIOG_CLK_ENABLE();
  __HAL_RCC_GPIOD_CLK_ENABLE();

  /*Configure GPIO pin Output Level */
  HAL_GPIO_WritePin(GPIOB, GPIO_PIN_0|GPIO_PIN_14|GPIO_PIN_7|GPIO_PIN_8, GPIO_PIN_RESET);

  /*Configure GPIO pin Output Level */
  HAL_GPIO_WritePin(GPIOF, GPIO_PIN_12|GPIO_PIN_13|GPIO_PIN_14|GPIO_PIN_15, GPIO_PIN_RESET);

  /*Configure GPIO pin Output Level */
  HAL_GPIO_WritePin(GPIOE, GPIO_PIN_8|GPIO_PIN_9|GPIO_PIN_11|GPIO_PIN_13
                          |GPIO_PIN_14|GPIO_PIN_15, GPIO_PIN_RESET);

  /*Configure GPIO pin Output Level */
  HAL_GPIO_WritePin(GPIOD, GPIO_PIN_14|GPIO_PIN_15, GPIO_PIN_RESET);

  /*Configure GPIO pin Output Level */
  HAL_GPIO_WritePin(GPIOG, GPIO_PIN_6|GPIO_PIN_9|GPIO_PIN_14, GPIO_PIN_RESET);

  /*Configure GPIO pins : PE3 PE4 PE5 PE6 */
  GPIO_InitStruct.Pin = GPIO_PIN_3|GPIO_PIN_4|GPIO_PIN_5|GPIO_PIN_6;
  GPIO_InitStruct.Mode = GPIO_MODE_INPUT;
  GPIO_InitStruct.Pull = GPIO_NOPULL;
  HAL_GPIO_Init(GPIOE, &GPIO_InitStruct);

  /*Configure GPIO pin : PC13 */
  GPIO_InitStruct.Pin = GPIO_PIN_13;
  GPIO_InitStruct.Mode = GPIO_MODE_IT_RISING;
  GPIO_InitStruct.Pull = GPIO_NOPULL;
  HAL_GPIO_Init(GPIOC, &GPIO_InitStruct);

  /*Configure GPIO pins : PF0 PF1 PF2 PF7
                           PF8 PF9 */
  GPIO_InitStruct.Pin = GPIO_PIN_0|GPIO_PIN_1|GPIO_PIN_2|GPIO_PIN_7
                          |GPIO_PIN_8|GPIO_PIN_9;
  GPIO_InitStruct.Mode = GPIO_MODE_INPUT;
  GPIO_InitStruct.Pull = GPIO_NOPULL;
  HAL_GPIO_Init(GPIOF, &GPIO_InitStruct);

  /*Configure GPIO pins : PF3 PF5 PF10 */
  GPIO_InitStruct.Pin = GPIO_PIN_3|GPIO_PIN_5|GPIO_PIN_10;
  GPIO_InitStruct.Mode = GPIO_MODE_ANALOG;
  GPIO_InitStruct.Pull = GPIO_NOPULL;
  HAL_GPIO_Init(GPIOF, &GPIO_InitStruct);

  /*Configure GPIO pins : PC0 PC3 */
  GPIO_InitStruct.Pin = GPIO_PIN_0|GPIO_PIN_3;
  GPIO_InitStruct.Mode = GPIO_MODE_ANALOG;
  GPIO_InitStruct.Pull = GPIO_NOPULL;
  HAL_GPIO_Init(GPIOC, &GPIO_InitStruct);

  /*Configure GPIO pins : PC1 PC4 PC5 */
  GPIO_InitStruct.Pin = GPIO_PIN_1|GPIO_PIN_4|GPIO_PIN_5;
  GPIO_InitStruct.Mode = GPIO_MODE_AF_PP;
  GPIO_InitStruct.Pull = GPIO_NOPULL;
  GPIO_InitStruct.Speed = GPIO_SPEED_FREQ_VERY_HIGH;
  GPIO_InitStruct.Alternate = GPIO_AF11_ETH;
  HAL_GPIO_Init(GPIOC, &GPIO_InitStruct);

  /*Configure GPIO pins : PA1 PA2 PA7 */
  GPIO_InitStruct.Pin = GPIO_PIN_1|GPIO_PIN_2|GPIO_PIN_7;
  GPIO_InitStruct.Mode = GPIO_MODE_AF_PP;
  GPIO_InitStruct.Pull = GPIO_NOPULL;
  GPIO_InitStruct.Speed = GPIO_SPEED_FREQ_VERY_HIGH;
  GPIO_InitStruct.Alternate = GPIO_AF11_ETH;
  HAL_GPIO_Init(GPIOA, &GPIO_InitStruct);

  /*Configure GPIO pin : PA3 */
  GPIO_InitStruct.Pin = GPIO_PIN_3;
  GPIO_InitStruct.Mode = GPIO_MODE_ANALOG;
  GPIO_InitStruct.Pull = GPIO_NOPULL;
  HAL_GPIO_Init(GPIOA, &GPIO_InitStruct);

  /*Configure GPIO pin : PA4 */
  GPIO_InitStruct.Pin = GPIO_PIN_4;
  GPIO_InitStruct.Mode = GPIO_MODE_INPUT;
  GPIO_InitStruct.Pull = GPIO_PULLUP;
  HAL_GPIO_Init(GPIOA, &GPIO_InitStruct);

  /*Configure GPIO pins : PB0 PB14 PB7 PB8 */
  GPIO_InitStruct.Pin = GPIO_PIN_0|GPIO_PIN_14|GPIO_PIN_7|GPIO_PIN_8;
  GPIO_InitStruct.Mode = GPIO_MODE_OUTPUT_PP;
  GPIO_InitStruct.Pull = GPIO_NOPULL;
  GPIO_InitStruct.Speed = GPIO_SPEED_FREQ_LOW;
  HAL_GPIO_Init(GPIOB, &GPIO_InitStruct);

  /*Configure GPIO pin : PB1 */
  GPIO_InitStruct.Pin = GPIO_PIN_1;
  GPIO_InitStruct.Mode = GPIO_MODE_ANALOG;
  GPIO_InitStruct.Pull = GPIO_NOPULL;
  HAL_GPIO_Init(GPIOB, &GPIO_InitStruct);

  /*Configure GPIO pins : PF12 PF13 PF14 PF15 */
  GPIO_InitStruct.Pin = GPIO_PIN_12|GPIO_PIN_13|GPIO_PIN_14|GPIO_PIN_15;
  GPIO_InitStruct.Mode = GPIO_MODE_OUTPUT_PP;
  GPIO_InitStruct.Pull = GPIO_NOPULL;
  GPIO_InitStruct.Speed = GPIO_SPEED_FREQ_LOW;
  HAL_GPIO_Init(GPIOF, &GPIO_InitStruct);

  /*Configure GPIO pins : PG1 PG7 */
  GPIO_InitStruct.Pin = GPIO_PIN_1|GPIO_PIN_7;
  GPIO_InitStruct.Mode = GPIO_MODE_INPUT;
  GPIO_InitStruct.Pull = GPIO_NOPULL;
  HAL_GPIO_Init(GPIOG, &GPIO_InitStruct);

  /*Configure GPIO pin : PE7 */
  GPIO_InitStruct.Pin = GPIO_PIN_7;
  GPIO_InitStruct.Mode = GPIO_MODE_AF_PP;
  GPIO_InitStruct.Pull = GPIO_NOPULL;
  GPIO_InitStruct.Speed = GPIO_SPEED_FREQ_VERY_HIGH;
  GPIO_InitStruct.Alternate = GPIO_AF8_UART7;
  HAL_GPIO_Init(GPIOE, &GPIO_InitStruct);

  /*Configure GPIO pins : PE8 PE9 PE11 PE13
                           PE14 PE15 */
  GPIO_InitStruct.Pin = GPIO_PIN_8|GPIO_PIN_9|GPIO_PIN_11|GPIO_PIN_13
                          |GPIO_PIN_14|GPIO_PIN_15;
  GPIO_InitStruct.Mode = GPIO_MODE_OUTPUT_PP;
  GPIO_InitStruct.Pull = GPIO_NOPULL;
  GPIO_InitStruct.Speed = GPIO_SPEED_FREQ_LOW;
  HAL_GPIO_Init(GPIOE, &GPIO_InitStruct);

  /*Configure GPIO pins : PB12 PB4 PB5 */
  GPIO_InitStruct.Pin = GPIO_PIN_12|GPIO_PIN_4|GPIO_PIN_5;
  GPIO_InitStruct.Mode = GPIO_MODE_INPUT;
  GPIO_InitStruct.Pull = GPIO_PULLUP;
  HAL_GPIO_Init(GPIOB, &GPIO_InitStruct);

  /*Configure GPIO pin : PB13 */
  GPIO_InitStruct.Pin = GPIO_PIN_13;
  GPIO_InitStruct.Mode = GPIO_MODE_AF_PP;
  GPIO_InitStruct.Pull = GPIO_NOPULL;
  GPIO_InitStruct.Speed = GPIO_SPEED_FREQ_VERY_HIGH;
  GPIO_InitStruct.Alternate = GPIO_AF11_ETH;
  HAL_GPIO_Init(GPIOB, &GPIO_InitStruct);

  /*Configure GPIO pins : PB15 PB9 */
  GPIO_InitStruct.Pin = GPIO_PIN_15|GPIO_PIN_9;
  GPIO_InitStruct.Mode = GPIO_MODE_INPUT;
  GPIO_InitStruct.Pull = GPIO_NOPULL;
  HAL_GPIO_Init(GPIOB, &GPIO_InitStruct);

  /*Configure GPIO pins : PD8 PD9 */
  GPIO_InitStruct.Pin = GPIO_PIN_8|GPIO_PIN_9;
  GPIO_InitStruct.Mode = GPIO_MODE_AF_PP;
  GPIO_InitStruct.Pull = GPIO_NOPULL;
  GPIO_InitStruct.Speed = GPIO_SPEED_FREQ_VERY_HIGH;
  GPIO_InitStruct.Alternate = GPIO_AF7_USART3;
  HAL_GPIO_Init(GPIOD, &GPIO_InitStruct);

  /*Configure GPIO pins : PD14 PD15 */
  GPIO_InitStruct.Pin = GPIO_PIN_14|GPIO_PIN_15;
  GPIO_InitStruct.Mode = GPIO_MODE_OUTPUT_PP;
  GPIO_InitStruct.Pull = GPIO_NOPULL;
  GPIO_InitStruct.Speed = GPIO_SPEED_FREQ_LOW;
  HAL_GPIO_Init(GPIOD, &GPIO_InitStruct);

  /*Configure GPIO pins : PG2 PG3 PG4 */
  GPIO_InitStruct.Pin = GPIO_PIN_2|GPIO_PIN_3|GPIO_PIN_4;
  GPIO_InitStruct.Mode = GPIO_MODE_INPUT;
  GPIO_InitStruct.Pull = GPIO_PULLUP;
  HAL_GPIO_Init(GPIOG, &GPIO_InitStruct);

  /*Configure GPIO pins : PG6 PG9 PG14 */
  GPIO_InitStruct.Pin = GPIO_PIN_6|GPIO_PIN_9|GPIO_PIN_14;
  GPIO_InitStruct.Mode = GPIO_MODE_OUTPUT_PP;
  GPIO_InitStruct.Pull = GPIO_NOPULL;
  GPIO_InitStruct.Speed = GPIO_SPEED_FREQ_LOW;
  HAL_GPIO_Init(GPIOG, &GPIO_InitStruct);

  /*Configure GPIO pins : PC9 PC10 PC11 PC12 */
  GPIO_InitStruct.Pin = GPIO_PIN_9|GPIO_PIN_10|GPIO_PIN_11|GPIO_PIN_12;
  GPIO_InitStruct.Mode = GPIO_MODE_INPUT;
  GPIO_InitStruct.Pull = GPIO_PULLUP;
  HAL_GPIO_Init(GPIOC, &GPIO_InitStruct);

  /*Configure GPIO pins : PA8 PA10 PA11 PA12 */
  GPIO_InitStruct.Pin = GPIO_PIN_8|GPIO_PIN_10|GPIO_PIN_11|GPIO_PIN_12;
  GPIO_InitStruct.Mode = GPIO_MODE_AF_PP;
  GPIO_InitStruct.Pull = GPIO_NOPULL;
  GPIO_InitStruct.Speed = GPIO_SPEED_FREQ_VERY_HIGH;
  GPIO_InitStruct.Alternate = GPIO_AF10_OTG_FS;
  HAL_GPIO_Init(GPIOA, &GPIO_InitStruct);

  /*Configure GPIO pin : PA9 */
  GPIO_InitStruct.Pin = GPIO_PIN_9;
  GPIO_InitStruct.Mode = GPIO_MODE_INPUT;
  GPIO_InitStruct.Pull = GPIO_NOPULL;
  HAL_GPIO_Init(GPIOA, &GPIO_InitStruct);

  /*Configure GPIO pin : PA15 */
  GPIO_InitStruct.Pin = GPIO_PIN_15;
  GPIO_InitStruct.Mode = GPIO_MODE_INPUT;
  GPIO_InitStruct.Pull = GPIO_NOPULL;
  HAL_GPIO_Init(GPIOA, &GPIO_InitStruct);

  /*Configure GPIO pin : PD0 */
  GPIO_InitStruct.Pin = GPIO_PIN_0;
  GPIO_InitStruct.Mode = GPIO_MODE_INPUT;
  GPIO_InitStruct.Pull = GPIO_NOPULL;
  HAL_GPIO_Init(GPIOD, &GPIO_InitStruct);

  /*Configure GPIO pins : PD4 PD5 PD6 PD7 */
  GPIO_InitStruct.Pin = GPIO_PIN_4|GPIO_PIN_5|GPIO_PIN_6|GPIO_PIN_7;
  GPIO_InitStruct.Mode = GPIO_MODE_INPUT;
  GPIO_InitStruct.Pull = GPIO_PULLUP;
  HAL_GPIO_Init(GPIOD, &GPIO_InitStruct);

  /*Configure GPIO pins : PG11 PG13 */
  GPIO_InitStruct.Pin = GPIO_PIN_11|GPIO_PIN_13;
  GPIO_InitStruct.Mode = GPIO_MODE_AF_PP;
  GPIO_InitStruct.Pull = GPIO_NOPULL;
  GPIO_InitStruct.Speed = GPIO_SPEED_FREQ_VERY_HIGH;
  GPIO_InitStruct.Alternate = GPIO_AF11_ETH;
  HAL_GPIO_Init(GPIOG, &GPIO_InitStruct);

}

/* mainCycleStart function */
void mainCycleStart(void const * argument)
{

  /* USER CODE BEGIN 5 */
  /* Infinite loop */

	int led_on = 0;

	//Initialisierung
	vInitModules(&System_State);

	/*ingredient_t testDrink1;
	testDrink1.amount = 100.0;
	testDrink1.bottleID = 1;
	testDrink1.lastInstruction = FALSE;

	ingredient_t testDrink2;
	testDrink2.amount = 100.0;
	testDrink2.bottleID = 0;
	testDrink2.lastInstruction = TRUE;

	list_append(&System_State.Gravity.drinkList, testDrink1);
	list_append(&System_State.Gravity.drinkList, testDrink2);*/

  while(1)
  {
	  if(led_on == 0)
	  {
		  BSP_LED_On(LED2);
		  led_on=1;
	  }
	  else
	  {
		  BSP_LED_Off(LED2);
		  led_on=0;
	  }

	  TickType_t startTicks = xTaskGetTickCount();

	  //Read Sensors
	  vReadSensorValues(&Input_Storage);

	  //Calculate Output
	  //vEvaluate_Module_5_Sensors(Input_Storage, &(System_State.Sensors), &(Output_Storage));
	  //vEvaluate_Module_6_Handling(Input_Storage, &(System_State.Handling), &(Output_Storage));
	  vEvaluate(Input_Storage, &System_State, &Output_Storage);

	  //Set output
	  vWriteActuatorValues(&Output_Storage);

	  TickType_t endTicks = xTaskGetTickCount();
	  int time_diff = (int)endTicks-(int)startTicks;
	  printf("Main Cycle End: Needed %d Ticks\r\n", time_diff);
	  printf("%s\n", "=============");

	  vTaskDelayUntil(&startTicks,100);

  }
  /* USER CODE END 5 */
}

/* initCommTask function */
void initCommTask(void const * argument)
{
  /* USER CODE BEGIN initCommTask */
	for(;;)
		{osDelay(1);}

  /* USER CODE END initCommTask */
}

/* TestEnvCallback function */
void TestEnvCallback(void const * argument)
{
  /* USER CODE BEGIN TestEnvCallback */
  if(virtual_testenv_timer_variable >= 75)
  {
	  virtual_testenv_timer_variable = 0;
  } else {
	  virtual_testenv_timer_variable++;
  }
  /* USER CODE END TestEnvCallback */
}

void HAL_TIM_PeriodElapsedCallback(TIM_HandleTypeDef *htim)
{
  if (htim->Instance == TIM1) {
    HAL_IncTick();
  }
}

void _Error_Handler(char * file, int line)
{
  while(1)
  {
  }
}

#ifdef USE_FULL_ASSERT

/**
   * @brief Reports the name of the source file and the source line number
   * where the assert_param error has occurred.
   * @param file: pointer to the source file name
   * @param line: assert_param error line source number
   * @retval None
   */
void assert_failed(uint8_t* file, uint32_t line)
{
  /* USER CODE BEGIN 6 */
  printf("Error in file %s, line %d\n",file, line)
  /* USER CODE END 6 */

}

#endif

/************************ (C) COPYRIGHT STMicroelectronics *****END OF FILE****/
